VERSION ""

NS_ :

BS_:

BU_: GCU TSMaster

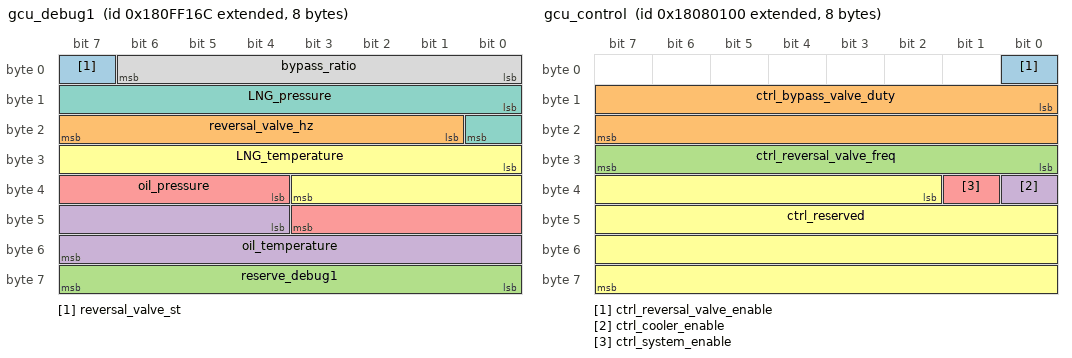
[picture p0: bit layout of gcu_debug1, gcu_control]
BO_ 2551181676 gcu_debug1: 8 GCU
 SG_ reversal_valve_st : 7|1@1+ (1,0) [0|1] "" Vector__XXX
 SG_ reversal_valve_hz : 17|7@1+ (1,0) [0|100] "Hz" Vector__XXX
 SG_ reserve_debug1 : 56|8@1+ (1,0) [0|255] "" Vector__XXX
 SG_ oil_temperature : 44|12@1+ (0.1,-80) [-80|90] "C" Vector__XXX
 SG_ oil_pressure : 36|8@1+ (0.1,0) [0|20] "MPa" Vector__XXX
 SG_ LNG_temperature : 24|12@1+ (0.1,-80) [-80|90] "C" Vector__XXX
 SG_ LNG_pressure : 8|9@1+ (0.1,0) [0|40] "MPa" Vector__XXX
 SG_ bypass_ratio : 0|7@1+ (1,0) [0|50] "%" Vector__XXX

BO_ 2550661376 gcu_control: 8 TSMaster
 SG_ ctrl_reversal_valve_enable : 0|1@1+ (1,0) [0|1] ""  GCU
 SG_ ctrl_bypass_valve_duty : 8|16@1+ (0.1,0) [0|100] "%"  GCU
 SG_ ctrl_reversal_valve_freq : 24|8@1+ (1,0) [0|100] "Hz"  GCU
 SG_ ctrl_cooler_enable : 32|1@1+ (1,0) [0|1] ""  GCU
 SG_ ctrl_system_enable : 33|1@1+ (1,0) [0|1] ""  GCU
 SG_ ctrl_reserved : 34|30@1+ (1,0) [0|1073741823] ""  GCU

CM_ SG_ 2551181676 reversal_valve_st "Reversal Valve Switch Status";
CM_ SG_ 2551181676 reversal_valve_hz "Reversal Valve Frequency";
CM_ SG_ 2551181676 reserve_debug1 "Reserved";
CM_ SG_ 2551181676 oil_temperature "Oil Temperature";
CM_ SG_ 2551181676 oil_pressure "Oil Pressure (0-20Mpa)";
CM_ SG_ 2551181676 LNG_temperature "LNG Buffer Tank Temperature";
CM_ SG_ 2551181676 LNG_pressure "LNG Buffer Tank Pressure";
CM_ SG_ 2551181676 bypass_ratio "Bypass Valve Opening Ratio";
CM_ SG_ 2550661376 ctrl_reversal_valve_enable "Control Command: Reversal Valve Enable (0=OFF, 1=ON)";
CM_ SG_ 2550661376 ctrl_bypass_valve_duty "Control Command: Bypass Valve Duty (0-100%)";
CM_ SG_ 2550661376 ctrl_reversal_valve_freq "Control Command: Reversal Valve Frequency (0-100 Hz)";
CM_ SG_ 2550661376 ctrl_cooler_enable "Control Command: Cooler Enable (0=OFF, 1=ON)";
CM_ SG_ 2550661376 ctrl_system_enable "Control Command: System Enable (0=Disable, 1=Enable)";
CM_ SG_ 2550661376 ctrl_reserved "Reserved for future use";
BA_DEF_ BO_  "GenMsgCycleTime" INT 0 10000;
BA_DEF_ BO_  "GenMsgSendType" STRING ;
BA_DEF_DEF_  "GenMsgCycleTime" 0;
BA_DEF_DEF_  "GenMsgSendType" "";
BA_ "GenMsgSendType" BO_ 2551181676 "Cyclic";
BA_ "GenMsgCycleTime" BO_ 2551181676 10;
BA_ "GenMsgSendType" BO_ 2550661376 "IfActive";
BA_ "GenMsgCycleTime" BO_ 2550661376 100;
VAL_ 2550661376 ctrl_reversal_valve_enable 0 "OFF" 1 "ON" ;
VAL_ 2550661376 ctrl_cooler_enable 0 "OFF" 1 "ON" ;
VAL_ 2550661376 ctrl_system_enable 0 "Disable" 1 "Enable" ;
